# RS1xxxx register map
Vendor: Silicon Lab Inc.; Series: ARMCM4; File version: 1.2
CPU: CM4 r1p0, little endian, MPU, FPU, 6 interrupt priority bits
Registers are 32-bit, read-write, reset 0x0 unless marked. A register's access mark holds for its fields unless they carry their own. Offsets are from the block's base; [hi:lo] are bit positions; lines under a group give offsets from that group; {n}, {i} and the like mark numbered series; 'fields as' and 'values as' point back to an identical list.

## QSPI — The queued serial peripheral interface module provides a serial peripheral interface with queued transfer capability
Base 0x12000000
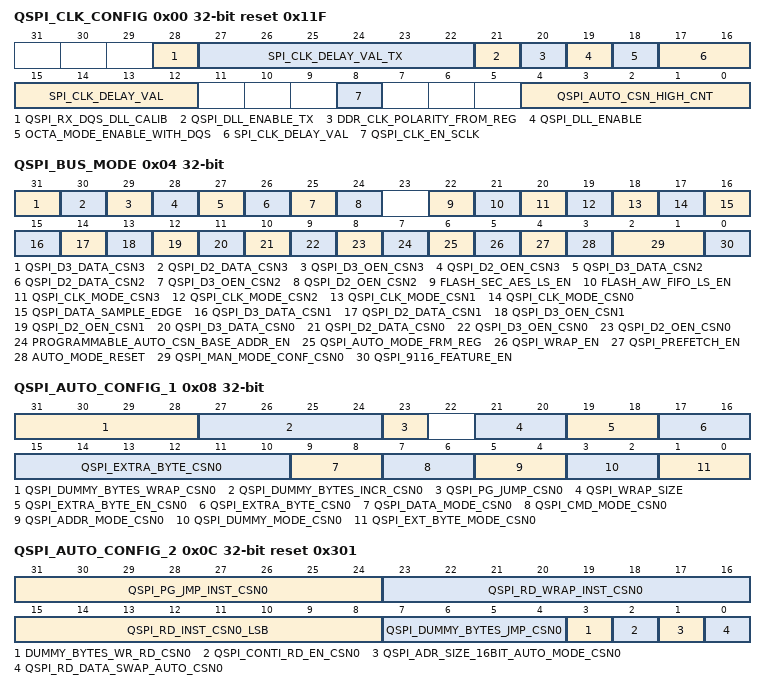
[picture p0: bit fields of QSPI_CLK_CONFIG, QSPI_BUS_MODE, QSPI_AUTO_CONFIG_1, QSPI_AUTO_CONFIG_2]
0x00 QSPI_CLK_CONFIG reset 0x11F (reset mask 0xFFF) — QSPI Clock Configuration Register
  [28] QSPI_RX_DQS_DLL_CALIB — Delay value programmed to TX QSPI DLL in write path. This delay is used to delay the qspi clock output according to the requirement
  [27:22] SPI_CLK_DELAY_VAL_TX — Delay value programmed to TX QSPI DLL in write path. This delay is used to delay the qspi clock output according to the requirement
  [21] QSPI_DLL_ENABLE_TX — Enable for TX QSPI DLL in write path. This is used in M4SS QSPI DDR pads to delay the qspi clock output. 0–DLL is disabled bypassed 1–DLL is enabled
    0=Disabled (DLL is disabled/bypassed.); 1=Enabled (DLL is enabled)
  [20] DDR_CLK_POLARITY_FROM_REG — Used this bit to sample the data at posedge negedge after interface FFs with internal qspi clock 0-Sample at negedge 1-Sample at posedge
    0=Negative_Edge (Sample at Negative edge); 1=Positive_Edge (Sample at positive edge)
  [19] QSPI_DLL_ENABLE — Enable for RX QSPI DLL in read mode.This is used in M4SS QSPI DDR pads to delay the pad clock DQS input
    values as QSPI_DLL_ENABLE_TX
  [18] OCTA_MODE_ENABLE_WITH_DQS — Enables SPI octa mode along with DQS in DDR mode
  [17:12] SPI_CLK_DELAY_VAL — Delay value programmed to RX QSPI DLL on read side. This delay is used to delay the pad clock/DQS according to the requirement
  [8] QSPI_CLK_EN_SCLK — QSPI clock enable
    0=Dynamic_Clock_Gating_Enabled (Dynamic clock gating is enabled in side QSPI controller); 1=Full_Time_Clock_Enabled (Full time clock is enabled for QSPI controller.)
  [4:0] QSPI_AUTO_CSN_HIGH_CNT — Minimum SOC clock cycles, during which QSPI auto csn should be high between consecutive CSN assertions
0x04 QSPI_BUS_MODE
  [31] QSPI_D3_DATA_CSN3 — Value of SPI_IO3 in case of dual/single mode for chip select3 csn3
  [30] QSPI_D2_DATA_CSN3 — Value of SPI_IO2 in case of dual/single mode for chip select3 csn3
  [29] QSPI_D3_OEN_CSN3 — Direction Control for SPI_IO3 in case of dual/single mode for chip select3 csn3
  [28] QSPI_D2_OEN_CSN3 — Direction Control for SPI_IO2 in case of dual/single mode for chip select3 csn3
  [27] QSPI_D3_DATA_CSN2 — Value of SPI_IO3 in case of dual/single mode for chip select2 csn2
  [26] QSPI_D2_DATA_CSN2 — Value of SPI_IO2 in case of dual/single mode for chip select2 csn2
  [25] QSPI_D3_OEN_CSN2 — Direction Control for SPI_IO3 in case of dual/single mode for chip select2 csn2
  [24] QSPI_D2_OEN_CSN2 — Direction Control for SPI_IO2 in case of dual/single mode for chip select2 csn2
  [22] FLASH_SEC_AES_LS_EN — Qspi flash auto write fifo light sleep enable
  [21] FLASH_AW_FIFO_LS_EN — Qspi flash auto write fifo light sleep enable
  [20] QSPI_CLK_MODE_CSN3 — QSPI Clock Mode
    0=Mode 0, QSPI_CLK is low when QSPI_CS is high for chip select3 csn3; 1=Mode 3, QSPI_CLK is high when QSPI_CS is high for chip select3 csn3
  [19] QSPI_CLK_MODE_CSN2 — QSPI Clock Mode
    0=Mode 0 QSPI_CLK is low when QSPI_CS is high for chip select2 csn2; 1=Mode 3 QSPI_CLK is high when QSPI_CS is high for chip select2 csn2
  [18] QSPI_CLK_MODE_CSN1 — QSPI Clock Mode
    0=Mode 0, QSPI_CLK is low when QSPI_CS is high for chip select1 csn1; 1=Mode 3, QSPI_CLK is high when QSPI_CS is high for chip select1 csn1
  [17] QSPI_CLK_MODE_CSN0 — QSPI Clock Mode
    0=Mode 0, QSPI_CLK is low when QSPI_CS is high for chip select0 csn0; 1=Mode 3, QSPI_CLK is high when QSPI_CS is high for chip select0 csn0
  [16] QSPI_DATA_SAMPLE_EDGE — Samples MISO data on clock edges
    0=Disable (Pos edge of loop back spi_pad_clk); 1=Enable (Neg edge of loop back spi_pad_clk)
  [15] QSPI_D3_DATA_CSN1 — Value of SPI_IO3 in case of dual/single mode for chip select1 csn1
  [14] QSPI_D2_DATA_CSN1 — Direction Control for SPI_IO3 in case of dual/single mode for chip select1 csn1
  [13] QSPI_D3_OEN_CSN1 — Direction Control for SPI_IO3 in case of dual/single mode for chip select1 csn1
  [12] QSPI_D2_OEN_CSN1 — Direction Control for SPI_IO2 in case of dual/single mode for chip select1 csn1
  [11] QSPI_D3_DATA_CSN0 — Value of SPI_IO3 in case of dual/single mode for chip select0 csn0. It is used both in Auto and Manual Mode
  [10] QSPI_D2_DATA_CSN0 — Value of SPI_IO2 in case of dual/single mode for chip select0 csn0. It is used both in Auto and Manual Mode.
  [9] QSPI_D3_OEN_CSN0 — Direction Control for SPI_IO3 in case of dual/single mode for chip select0 csn0. It is used both in Auto and Manual Mode.
  [8] QSPI_D2_OEN_CSN0 — Direction Control for SPI_IO2 in case of dual/single mode for chip select0 csn0. It is used both in Auto and Manual Mode
  [7] PROGRAMMABLE_AUTO_CSN_BASE_ADDR_EN — Programmable auto csn mode enable
  [6] QSPI_AUTO_MODE_FRM_REG — QSPI Mode of Operation
    0=Disable (Manual Mode is selected); 1=Enable (Auto Mode is selected.)
  [5] QSPI_WRAP_EN — Model wrap is considered with this bit and uses wrap instruction to read from FLASH
    0=Disable (Wrap mode is disabled (AHB WRAP can be used).); 1=Enable (Wrap mode is enabled)
  [4] QSPI_PREFETCH_EN — Pre-fetch of data from the model which is connected to QSPI, automatically with out reading on AHB and is supplied to AHB, when address is matched with AHB read transaction address
    0=Disable (Pre-fetch mode is disabled.); 1=Enable (Pre-fetch mode is enabled)
  [3] AUTO_MODE_RESET — QSPI Auto controller reset. This is not a Self clearing bit
    0=Disable (Auto mode is active); 1=Enable (Auto mode is inactive)
  [2:1] QSPI_MAN_MODE_CONF_CSN0 — Configures the QSPI flash for Single/Dual/Quad mode operation in manual mode
    0=Single Mode; 1=Dual Mode; 2=Quad Mode; 3=none
  [0] QSPI_9116_FEATURE_EN — 9115 specific features are enabled with this enable
0x08 QSPI_AUTO_CONFIG_1 (reset mask 0xFF8FFFFF) — QSPI Auto Controller Configuration 1 Register
  [31:28] QSPI_DUMMY_BYTES_WRAP_CSN0 — Specifies the number of dummy bytes 0 to 7 for the selected SPI mode in case of wrap instruction
  [27:24] QSPI_DUMMY_BYTES_INCR_CSN0 — Specifies the number of dummy bytes 0 to 7 for the selected SPI mode
  [23] QSPI_PG_JUMP_CSN0
  [21:20] QSPI_WRAP_SIZE — Qspi auto wrap size
  [19:18] QSPI_EXTRA_BYTE_EN_CSN0 — Value of the extra byte to be transmitted, if the extra byte mode is enabled
    0=Do not transmit extra byte; 1=Transmit Extra byte after address phase; 2=Transmit only first nibble of the byte and maintain Hi-Z on the IO bus for next nibble; 3=none
  [17:10] QSPI_EXTRA_BYTE_CSN0 — Value of the extra byte to be transmitted, if the extra byte mode is enabled
  [9:8] QSPI_DATA_MODE_CSN0 — Mode of operation of QSPI in DATA phase
    0=SPI; 1=Dual SPI; 2=Quad SPI; 3=none
  [7:6] QSPI_CMD_MODE_CSN0 — Mode of operation of QSPI in instruction phase
    0=SPI; 1=Dual SPI; 2=Quad SPI; 3=none
  [5:4] QSPI_ADDR_MODE_CSN0 — Mode of operation of QSPI in instruction phase
    0=SPI; 1=Dual SPI; 2=Quad SPI; 3=none
  [3:2] QSPI_DUMMY_MODE_CSN0 — Mode of operation of QSPI in instruction phase
    0=SPI; 1=Dual SPI; 2=Quad SPI; 3=none
  [1:0] QSPI_EXT_BYTE_MODE_CSN0 — Mode of operation of QSPI in the extra byte phase
    0=SPI; 1=Dual SPI; 2=Quad SPI; 3=none
0x0C QSPI_AUTO_CONFIG_2 reset 0x301 — QSPI Auto Controller Configuration 2 Register
  [31:24] QSPI_PG_JMP_INST_CSN0 — Read instruction to be used, when Page jump is to be used
  [23:16] QSPI_RD_WRAP_INST_CSN0 — Read instruction to be used, when wrap mode is supported by QSPI flash
  [15:8] QSPI_RD_INST_CSN0_LSB — Read instruction LS Byte to be used for the selected SPI modes and when wrap is not supported
  [7:4] QSPI_DUMMY_BYTES_JMP_CSN0 — Dummy cycles to be selected in case of JUMP
  [3] DUMMY_BYTES_WR_RD_CSN0 — Dummy bytes to the model to be read or to be write
    0=Disable (Dummy bytes will be read); 1=Enable (Dummy bytes to be write.)
  [2] QSPI_CONTI_RD_EN_CSN0
    0=Disabled (Continuous read disabled.); 1=Enabled (Continuous read enabled.)
  [1] QSPI_ADR_SIZE_16BIT_AUTO_MODE_CSN0
    0=Disable (24 bit address is sent to model); 1=Enable (16 Bit address is sent to model)
  [0] QSPI_RD_DATA_SWAP_AUTO_CSN0
    0=Disable (Do not swap the read data in auto mode); 1=Enable (Swap the auto read data in auto mode)
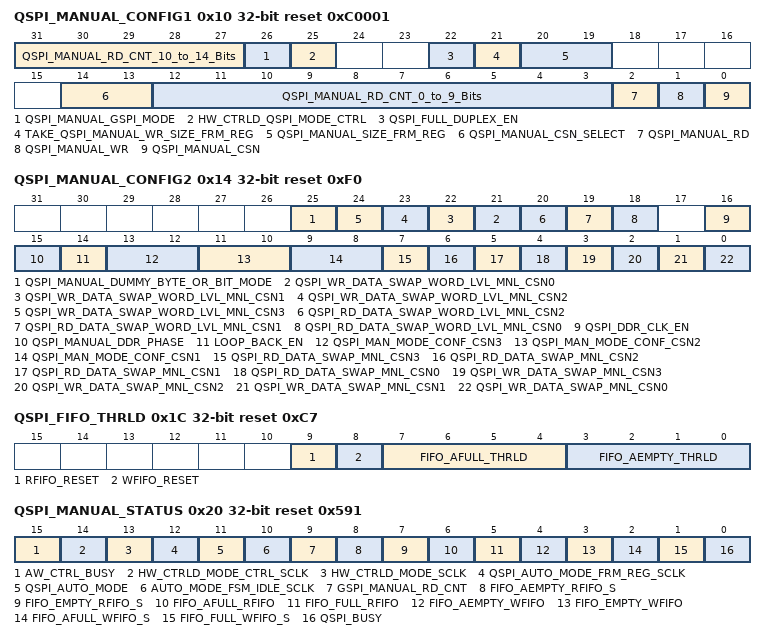
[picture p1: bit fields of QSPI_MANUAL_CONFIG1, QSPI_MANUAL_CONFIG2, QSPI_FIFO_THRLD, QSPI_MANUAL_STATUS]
0x10 QSPI_MANUAL_CONFIG1 reset 0xC0001 — QSPI Manual Configuration 1 Register
  [31:27] QSPI_MANUAL_RD_CNT_10_to_14_Bits — Indicates total number of bytes or bits
  [26] QSPI_MANUAL_GSPI_MODE — Internally the priority is given to manual mode
    0=SPI_Mode; 1=Host_SPI_Mode
  [25] HW_CTRLD_QSPI_MODE_CTRL — Hardware controlled qspi mode in between AUTO and manual
    0=Disabled (Hardware control is disabled); 1=Enabled (Hardware control is enabled.)
  [22] QSPI_FULL_DUPLEX_EN — Full duplex mode enable.
    0=Disable (Full duplex mode disabled.); 1=Enable (Full duplex mode enabled)
  [21] TAKE_QSPI_MANUAL_WR_SIZE_FRM_REG
    0=Disable (No action. Takes write size from fifo); 1=Enable (Take write size from Manual config register1)
  [20:19] QSPI_MANUAL_SIZE_FRM_REG — Manual reads and manual writes follow this size
  [14:13] QSPI_MANUAL_CSN_SELECT — Indicates which CSn is valid
  [12:3] QSPI_MANUAL_RD_CNT_0_to_9_Bits — Indicates total number of bytes to be read along with [31:27] bits of this register. Maximum length supported is 32k bytes
  [2] QSPI_MANUAL_RD — Read enable for manual mode when CS is low
  [1] QSPI_MANUAL_WR — Write enable for manual mode when CS is low
  [0] QSPI_MANUAL_CSN — SPI CS in manual mode
0x14 QSPI_MANUAL_CONFIG2 reset 0xF0 (reset mask 0xFFF) — QSPI Manual Configuration 2 Register
  [25] QSPI_MANUAL_DUMMY_BYTE_OR_BIT_MODE — Indicates qspi_manual_rd_cnt values are dummy bytes or bits in manual mode.
  [n+21] QSPI_WR_DATA_SWAP_WORD_LVL_MNL_CSN{n} (n=0..3) — Set this bit for write data byte swapping within the word. It is valid only for octa ddr mode. It is valid for csn{n}.
  [20] QSPI_RD_DATA_SWAP_WORD_LVL_MNL_CSN2 — Set this bit for read data byte swapping within the word. It is valid only for octa ddr mode. It is valid for csn2.
  [19] QSPI_RD_DATA_SWAP_WORD_LVL_MNL_CSN1 — Set this bit for read data byte swapping within the word. It is valid only for octa ddr mode. It is valid for csn1.
  [18] QSPI_RD_DATA_SWAP_WORD_LVL_MNL_CSN0 — Set this bit for read data byte swapping within the word. It is valid only for octa ddr mode. It is valid for csn0.
  [16] QSPI_DDR_CLK_EN — DDR operations can be performed even in manual mode
    0=Disable (Use SDR mode clk); 1=Enable (Use DDR mode clk)
  [15] QSPI_MANUAL_DDR_PHASE — DDR operations can be performed even in manual mode
  [14] LOOP_BACK_EN — Internal loop back test mode.
  [13:12] QSPI_MAN_MODE_CONF_CSN3 — Configures the QSPI flash for Single or Dual or Quad mode operation in manual mode for chip select3 csn3
    0=Single; 1=Dual; 2=Quad; 3=none
  [11:10] QSPI_MAN_MODE_CONF_CSN2 — Configures the QSPI flash for Single or Dual or Quad mode operation in manual mode for chip select2 csn2
    0=Single; 1=Dual; 2=Quad; 3=none
  [9:8] QSPI_MAN_MODE_CONF_CSN1 — Configures the QSPI flash for Single/Dual/Quad mode operation in manual mode for chip select1 csn1
    0=Single; 1=Dual; 2=Quad; 3=none
  [7] QSPI_RD_DATA_SWAP_MNL_CSN3 — Swap the read data inside the QSPIcontroller itself
    0=Disable (Manual read data swap is disabled for csn3); 1=Enable (Manual read data swap is enabled for csn3)
  [6] QSPI_RD_DATA_SWAP_MNL_CSN2 — Swap the read data inside the QSPIcontroller it-self
    0=Disable (Manual read data swap is disabled for csn2); 1=Enable (Manual read data swap is enabled for csn2)
  [5] QSPI_RD_DATA_SWAP_MNL_CSN1 — Swap the read data inside the QSPIcontroller itself.
    0=Disable (Manual read data swap is disabled for csn1); 1=Enable (Manual read data swap is enabled for csn1)
  [4] QSPI_RD_DATA_SWAP_MNL_CSN0 — Swap the read data inside the QSPIcontroller it self.
    0=Disable (Manual read data swap is disabled for csn0.); 1=Enable (Manual read data swap is enabled for csn0.)
  [3] QSPI_WR_DATA_SWAP_MNL_CSN3 — Swap the write data inside the QSPI controller itself.
    0=Disable (Manual write data swap is disabled for csn3.); 1=Enable (Manual write data swap is enabled for csn3.)
  [2] QSPI_WR_DATA_SWAP_MNL_CSN2 — Swap the write data inside the QSPI controller itself.
    0=Disable (Manual write data swap is disabled for csn2.); 1=Enable (Manual write data swap is enabled for csn2.)
  [1] QSPI_WR_DATA_SWAP_MNL_CSN1 — Swap the write data inside the QSPI controller it-self.
    0=Disable (Manual write data swap is disabled for csn1.); 1=Enable (Manual write data swap is enabled for csn1.)
  [0] QSPI_WR_DATA_SWAP_MNL_CSN0 — Swap the write data inside the QSPI controller it-self
    0=Disable (Manual write data swap is disabled for csn0.); 1=Enable (Manual write data swap is enabled for csn0.)
0x1C QSPI_FIFO_THRLD reset 0xC7 (reset mask 0x1FF) — QSPI FIFO Threshold Register
  [9] RFIFO_RESET — Read fifo reset
  [8] WFIFO_RESET — Write fifo reset
  [7:4] FIFO_AFULL_THRLD — FIFO almost full threshold
  [3:0] FIFO_AEMPTY_THRLD — FIFO almost empty threshold
0x20 QSPI_MANUAL_STATUS ro reset 0x591 (reset mask 0x7FFF)
  [15] AW_CTRL_BUSY — Auto write busy indication.
  [14] HW_CTRLD_MODE_CTRL_SCLK — HW_CTRLD_MODE status
    0=Disable (HW_CTRL_MODE is disabled.); 1=Enable (HW_CTRL_MODE is enabled)
  [13] HW_CTRLD_MODE_SCLK — QSPI mode status in HW_CTRLD_MODE
    0=Disable (QSPI controller is in MANUAL mode.); 1=Enable (QSPI controller is working in AUTO MODE.)
  [12] QSPI_AUTO_MODE_FRM_REG_SCLK — QSPI auto mode status. Valid only when HW_CTRLD_QSPI_MODE_CTRL is zero.
    0=Disable (QSPI controller is hot coded to manual mode operations.); 1=Enable (QSPI controller is hot coded to AUTO mode operations)
  [11] QSPI_AUTO_MODE — QSPI controller status.
    0=Disable (QSPI controller is in manual mode.); 1=Enable (QSPI controller is in auto mode.)
  [10] AUTO_MODE_FSM_IDLE_SCLK — Auto mode idle signal to track auto controller is busy or idle.
    0=Disable (Auto mode is busy); 1=Enable (Auto mode is idle)
  [9] GSPI_MANUAL_RD_CNT — This is a result of 10 bits ORing counter
    0=Disable (No read transactions are in pending); 1=Enable (Read transactions are in pending ( to be done))
  [8] FIFO_AEMPTY_RFIFO_S — Status indication for Rfifo in manual mode
  [7] FIFO_EMPTY_RFIFO_S — Status indication for Rfifo in manual mode
  [6] FIFO_AFULL_RFIFO — Status indication for Rfifo in manual mode
  [5] FIFO_FULL_RFIFO — Status indication for Rfifo in manual mode
  [4] FIFO_AEMPTY_WFIFO — Status indication for Wfifo in manual mode
  [3] FIFO_EMPTY_WFIFO — Status indication for Wfifo in manual mode
  [2] FIFO_AFULL_WFIFO_S — Status indication for Wfifo in manual mode
  [1] FIFO_FULL_WFIFO_S — Status indication for Wfifo in manual mode
  [0] QSPI_BUSY — State of Manual mode.
    0=Disable (QSPI controller is IDLE in Manual mode.); 1=Enable (A read, write or dummy cycle operation is in process in manual mode.)
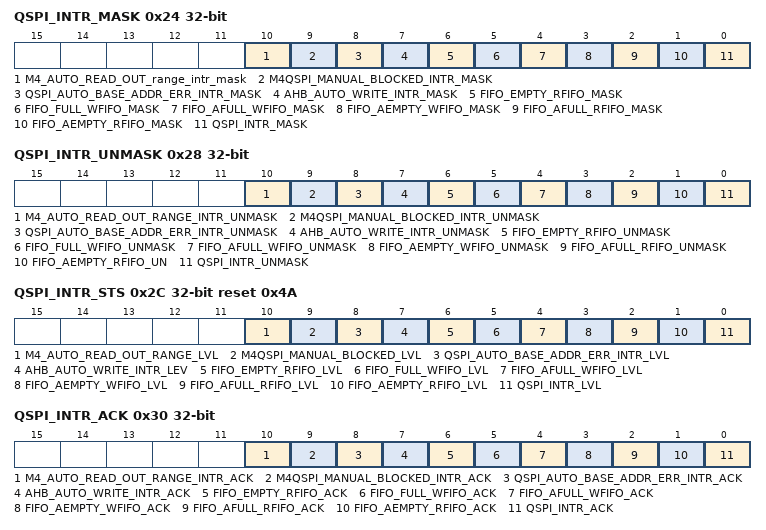
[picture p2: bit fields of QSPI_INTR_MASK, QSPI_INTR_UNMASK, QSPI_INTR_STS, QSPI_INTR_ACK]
0x24 QSPI_INTR_MASK (reset mask 0x6F) — QSPI Interrupt Mask Register
  [10] M4_AUTO_READ_OUT_range_intr_mask — Rising interrupt when M4 QSPI tries to read TA locations in Common flash mode (3). This bit is a mask for this interrupt.
  [9] M4QSPI_MANUAL_BLOCKED_INTR_MASK — Rising interrupt when M4 QSPI tries to do manual mode transactions in Common flash mode (3). This bit is a mask for this interrupt.
  [8] QSPI_AUTO_BASE_ADDR_ERR_INTR_MASK — Rising interrupt when no csn is selected using programmable auto base address. This bit is a mask for this interrupt.
  [7] AHB_AUTO_WRITE_INTR_MASK — Rising interrupt for any auto write operation on AHB bus. This bit is a mask for this interrupt
  [6] FIFO_EMPTY_RFIFO_MASK
    0=Disable (Do not touch); 1=Enable (Read fifo is empty intr mask)
  [5] FIFO_FULL_WFIFO_MASK
    0=Disable (Do not touch); 1=Enable (write fifo full intr mask)
  [4] FIFO_AFULL_WFIFO_MASK
    0=Disable (Do not touch); 1=Enable (Write fifo almost full intr mask)
  [3] FIFO_AEMPTY_WFIFO_MASK
    0=Disable (Do not touch); 1=Enable (write fifo almost empty intr mask.)
  [2] FIFO_AFULL_RFIFO_MASK
    0=Disable (Do not touch); 1=Enable (read fifo almost full intr mask)
  [1] FIFO_AEMPTY_RFIFO_MASK
    0=Disable (Do not touch); 1=Enable (Read fifo almost empty intr mask.)
  [0] QSPI_INTR_MASK — Interrupt Status bit
    0=Disable (Do not touch); 1=Enable (mask the qspi intr)
0x28 QSPI_INTR_UNMASK (reset mask 0x7F) — QSPI Interrupt Unmask Register
  [10] M4_AUTO_READ_OUT_RANGE_INTR_UNMASK — Rising interrupt when M4 QSPI tries to read TA locations in Common flash mode (3). This bit is a unmask for this interrupt.
  [9] M4QSPI_MANUAL_BLOCKED_INTR_UNMASK — Rising interrupt when M4 QSPI tries to do manual mode transactions in Common flash mode (3). This bit is a unmask for this interrupt.
  [8] QSPI_AUTO_BASE_ADDR_ERR_INTR_UNMASK — Rising interrupt when M4 QSPI tries to do manual mode transactions in Common flash mode (3). This bit is a unmask for this interrupt.
  [7] AHB_AUTO_WRITE_INTR_UNMASK — Rising interrupt for any auto write operation on AHB bus. This bit is a unmask for this interrupt.
  [6] FIFO_EMPTY_RFIFO_UNMASK
    0=Disable (Do not touch); 1=Enable (Read fifo is empty intr unmask)
  [5] FIFO_FULL_WFIFO_UNMASK
    0=Disable (Do not touch); 1=Enable (write fifo full intr unmask)
  [4] FIFO_AFULL_WFIFO_UNMASK
    0=Disable (Do not touch); 1=Enable (Write fifo almost full intr unmask.)
  [3] FIFO_AEMPTY_WFIFO_UNMASK
    0=Disable (Do not touch); 1=Enable (write fifo almost empty intr unmask)
  [2] FIFO_AFULL_RFIFO_UNMASK
    0=Disable (Do not touch); 1=Enable (read fifo almost full intr unmask.)
  [1] FIFO_AEMPTY_RFIFO_UN
    0=Disable (Do not touch); 1=Enable (Read fifo almost empty intr unmask)
  [0] QSPI_INTR_UNMASK — Interrupt Status bit
    0=Disable (Do not touch); 1=Enable (unmask the qspi intr)
0x2C QSPI_INTR_STS ro reset 0x4A (reset mask 0x7F) — QSPI Interrupt Status Register
  [10] M4_AUTO_READ_OUT_RANGE_LVL — Rising interrupt when M4 QSPI tries to read TA locations in Common flash mode (3).
  [9] M4QSPI_MANUAL_BLOCKED_LVL — Rising interrupt when M4 QSPI tries to do manual mode transactions in Common flash mode (3).
  [8] QSPI_AUTO_BASE_ADDR_ERR_INTR_LVL — Rising interrupt when no csn is selected using programmable auto base address.
  [7] AHB_AUTO_WRITE_INTR_LEV — rising interrupt for any auto write operation on AHB bus.
  [6] FIFO_EMPTY_RFIFO_LVL
    0=Disable (Read FIFO is not empty); 1=Enable (Read FIFO is empty)
  [5] FIFO_FULL_WFIFO_LVL
    0=Disable (Write fifo not got full); 1=Enable (write fifo got full.)
  [4] FIFO_AFULL_WFIFO_LVL
    0=Disable (write FIFO not reached almost full threshold); 1=Enable (Write FIFO reached almost full threshold)
  [3] FIFO_AEMPTY_WFIFO_LVL
    0=Disable (write FIFO not reached almost full threshold.); 1=Enable (write FIFO reached almost empty threshold.)
  [2] FIFO_AFULL_RFIFO_LVL
    0=Disable (read FIFO do not reached almost full threshold); 1=Enable (read FIFO reached almost full threshold)
  [1] FIFO_AEMPTY_RFIFO_LVL
    0=Disable (Read fifo does not reached almost empty threshold); 1=Enable (Read fifo reached almost empty threshold)
  [0] QSPI_INTR_LVL — Interrupt Status bit
    0=Disable (no interrupt); 1=Enable (qspi raised a interrupt)
0x30 QSPI_INTR_ACK (reset mask 0x7F) — QSPI Interrupt Acknowledge Register
  [10] M4_AUTO_READ_OUT_RANGE_INTR_ACK — Rising interrupt when M4 QSPI tries to read TA locations in Common flash mode (3). This bit is an ack for this interrupt.
  [9] M4QSPI_MANUAL_BLOCKED_INTR_ACK — Rising interrupt when M4 QSPI tries to do manual mode transactions in Common flash mode (3). This bit is an ack for this interrupt.
  [8] QSPI_AUTO_BASE_ADDR_ERR_INTR_ACK wo — Rising interrupt when no csn is selected using programmable auto base address. This bit is an ack for this interrupt.
  [7] AHB_AUTO_WRITE_INTR_ACK wo — Rising interrupt for any auto write operation on AHB bus. This bit is an ack for this interrupt.
  [6] FIFO_EMPTY_RFIFO_ACK wo
    values as QSPI_INTR_UNMASK.FIFO_EMPTY_RFIFO_UNMASK
  [5] FIFO_FULL_WFIFO_ACK wo
    values as QSPI_INTR_UNMASK.FIFO_FULL_WFIFO_UNMASK
  [4] FIFO_AFULL_WFIFO_ACK wo
    values as QSPI_INTR_UNMASK.FIFO_AFULL_WFIFO_UNMASK
  [3] FIFO_AEMPTY_WFIFO_ACK wo
    0=Disable (Do not touch); 1=Enable (write fifo almost empty intr unmask.)
  [2] FIFO_AFULL_RFIFO_ACK wo
    values as QSPI_INTR_UNMASK.FIFO_AFULL_RFIFO_UNMASK
  [1] FIFO_AEMPTY_RFIFO_ACK wo
    values as QSPI_INTR_UNMASK.FIFO_AEMPTY_RFIFO_UN
  [0] QSPI_INTR_ACK wo — Interrupt Status bit
    0=Disable (Do not touch); 1=Enable (unmask the qspi intr.)
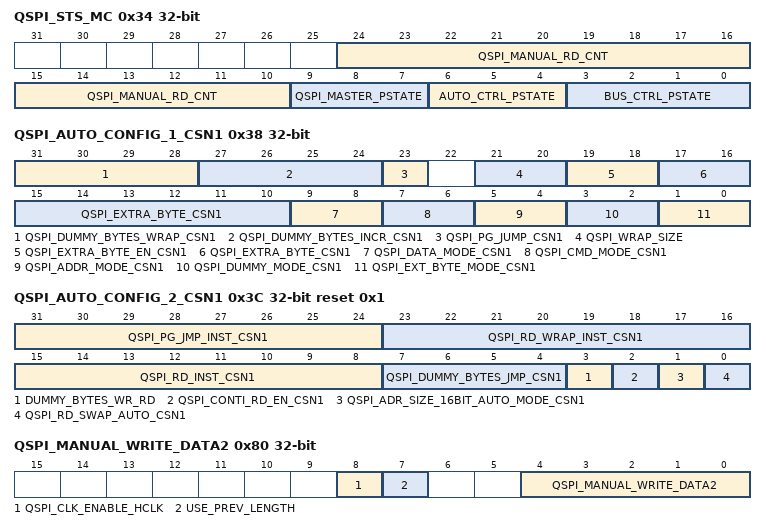
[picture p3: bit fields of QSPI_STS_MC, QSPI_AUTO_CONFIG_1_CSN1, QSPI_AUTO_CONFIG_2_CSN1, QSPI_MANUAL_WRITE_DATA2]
0x34 QSPI_STS_MC ro (reset mask 0x6FF) — QSPI State Machine Monitor Register
  [24:10] QSPI_MANUAL_RD_CNT — Qspi manual read counter value
  [9:7] QSPI_MASTER_PSTATE — Qspi master present state
  [6:4] AUTO_CTRL_PSTATE — Auto controller present state
  [3:0] BUS_CTRL_PSTATE — Bus controller present state
0x38 QSPI_AUTO_CONFIG_1_CSN1 (reset mask 0x87FFFF) — QSPI Auto Controller Configuration 1 CSN1 Register
  [31:28] QSPI_DUMMY_BYTES_WRAP_CSN1 ro — Specifies the number of dummy bytes 0 to 7 for the selected SPI mode in case of wrap instruction.
  [27:24] QSPI_DUMMY_BYTES_INCR_CSN1 ro — Specifies the number of dummy bytes 0 to 7 for the selected SPI mode.
  [23] QSPI_PG_JUMP_CSN1 wo
    0=Disable (Do not use Index jump instruction.); 1=Enable (Use Index jump instruction specified by QSPI_PG_JUMP_INST)
  [21:20] QSPI_WRAP_SIZE — Qspi auto wrap size
  [19:18] QSPI_EXTRA_BYTE_EN_CSN1 — Mode of operation of QSPI in DATA phase.
    values as QSPI_AUTO_CONFIG_1.QSPI_EXTRA_BYTE_EN_CSN0
  [17:10] QSPI_EXTRA_BYTE_CSN1 ro — Value of the extra byte to be transmitted, if the extra byte mode is enabled.
  [9:8] QSPI_DATA_MODE_CSN1 — Mode of operation of QSPI in DATA phase.
    0=SPI; 1=Dual SPI; 2=Quad SPI; 3=none
  [7:6] QSPI_CMD_MODE_CSN1 — Mode of operation of QSPI in instruction phase.
    0=SPI; 1=Dual SPI; 2=Quad SPI; 3=none
  [5:4] QSPI_ADDR_MODE_CSN1 — Mode of operation of QSPI in instruction phase.
    0=SPI; 1=Dual SPI; 2=Quad SPI; 3=none
  [3:2] QSPI_DUMMY_MODE_CSN1 — Mode of operation of QSPI in instruction phase
    0=SPI; 1=Dual SPI; 2=Quad SPI; 3=none
  [1:0] QSPI_EXT_BYTE_MODE_CSN1 — Mode of operation of QSPI in instruction phase.
    0=SPI; 1=Dual SPI; 2=Quad SPI; 3=none
0x3C QSPI_AUTO_CONFIG_2_CSN1 reset 0x1 — QSPI Auto Controller Configuration 2 CSN1 Register
  [31:24] QSPI_PG_JMP_INST_CSN1 — Read instruction to be used, when Page jump is to be used.
  [23:16] QSPI_RD_WRAP_INST_CSN1 — Read instruction to be used for the selected SPI modes and when wrap is not needed or supported
  [15:8] QSPI_RD_INST_CSN1 — Read instruction to be used for the selected SPI modes and when wrap is not needed or supported
  [7:4] QSPI_DUMMY_BYTES_JMP_CSN1 — Dummy cycles to be selected in case of JUMP
  [3] DUMMY_BYTES_WR_RD — Dummy bytes to the model to be read or to be write.
  [2] QSPI_CONTI_RD_EN_CSN1 — Continuous read enable bit.
  [1] QSPI_ADR_SIZE_16BIT_AUTO_MODE_CSN1
  [0] QSPI_RD_SWAP_AUTO_CSN1 — Swap the read data from the flash in byte order for chip select1 csn1 in auto mode.
    0=Swap_Disable (Swap is disabled.); 1=Swap_Enable (Swap is enabled)
0x80 QSPI_MANUAL_WRITE_DATA2 (reset mask 0xFF)
  [8] QSPI_CLK_ENABLE_HCLK — reserved2
  [7] USE_PREV_LENGTH — Use previous length.
    0=Disable (No action); 1=Enable (Uses previously programmed length in [4:0] of this register for next writes)
  [4:0] QSPI_MANUAL_WRITE_DATA2 — Number of bits to be written in write mode
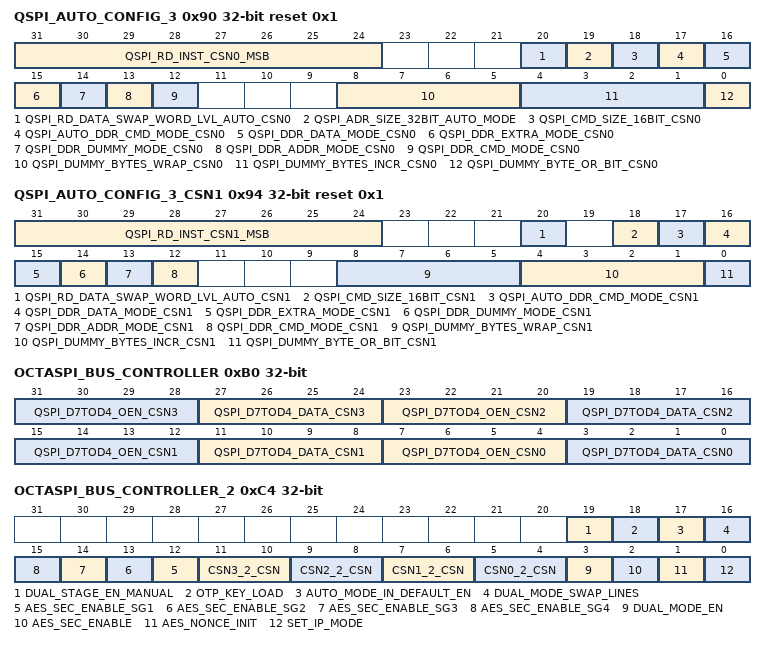
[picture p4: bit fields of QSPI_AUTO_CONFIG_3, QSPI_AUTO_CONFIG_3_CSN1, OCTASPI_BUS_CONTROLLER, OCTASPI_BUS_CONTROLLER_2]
0x90 QSPI_AUTO_CONFIG_3 reset 0x1 — QSPI Auto Controller Configuration 3 CSN0 Register
  [31:24] QSPI_RD_INST_CSN0_MSB — Read instruction MS byte to be used the selected SPI modes and when wrap is not needed or supported.
  [20] QSPI_RD_DATA_SWAP_WORD_LVL_AUTO_CSN0 — Rd data swap at word level in auto mode for csn0. It is valid for octa mode.
  [19] QSPI_ADR_SIZE_32BIT_AUTO_MODE — 32 bit addressing support enable.
  [18] QSPI_CMD_SIZE_16BIT_CSN0 — Enable for 16 read cmd size for csn0.
  [17] QSPI_AUTO_DDR_CMD_MODE_CSN0 — DDR data mode.
  [16] QSPI_DDR_DATA_MODE_CSN0 — DDR Address mode
    0=Disable (Data are sampled in SDR fashion); 1=Enable (Data are sampled in DDR fashion)
  [15] QSPI_DDR_EXTRA_MODE_CSN0 — DDR Address mode
    0=Disable (Extra byte is driven in SDR fashion); 1=Enable (Extra byte is driven in DDR fashion)
  [14] QSPI_DDR_DUMMY_MODE_CSN0 — DDR Address mode
    0=Disable (Dummy bytes are driven in SDR fashion); 1=Enable (Dummy bytes are driven in DDR fashion.)
  [13] QSPI_DDR_ADDR_MODE_CSN0 — DDR Address mode
    0=Disable (Address bytes are driven in SDR fashion); 1=Enable (Address bytes are driven in DDR fashion)
  [12] QSPI_DDR_CMD_MODE_CSN0 — DDR Command mode
    0=Disable (Command byte is driven in SDR fashion); 1=Enable (Command byte is driven in DDR fashion.)
  [8:5] QSPI_DUMMY_BYTES_WRAP_CSN0 — Specifies the number of dummy bytes for the selected SPI mode in case of wrap instruction. It contains MS nibble for byte.
  [4:1] QSPI_DUMMY_BYTES_INCR_CSN0 — Specifies the number of dummy bytes for the selected SPI mode. It contains MS nibble for byte.
  [0] QSPI_DUMMY_BYTE_OR_BIT_CSN0 — Indicates all above mention values are dummy bytes or bits in auto mode.
0x94 QSPI_AUTO_CONFIG_3_CSN1 reset 0x1 — QSPI Auto Controller Configuration 3 CSN1 Register
  [31:24] QSPI_RD_INST_CSN1_MSB — Read instruction MS byte to be used the selected SPI modes and when wrap is not needed or supported.
  [20] QSPI_RD_DATA_SWAP_WORD_LVL_AUTO_CSN1 — Rd data swap at word level in auto mode for csn1. It is valid for octa mode.
  [18] QSPI_CMD_SIZE_16BIT_CSN1 — Enable for 16 read cmd size for csn1.
  [17] QSPI_AUTO_DDR_CMD_MODE_CSN1 — DDR data mode.
  [16] QSPI_DDR_DATA_MODE_CSN1 — DDR Address mode
    0=Data are sampled in SDR fashion; 1=Data are sampled in DDR fashion
  [15] QSPI_DDR_EXTRA_MODE_CSN1 — DDR Address mode
    0=Extra byte is driven in SDR fashion; 1=Extra byte is driven in DDR fashion
  [14] QSPI_DDR_DUMMY_MODE_CSN1 — DDR Address mode
    0=Dummy bytes are driven in SDR fashion; 1=Dummy bytes are driven in DDR fashion
  [13] QSPI_DDR_ADDR_MODE_CSN1 — DDR Address mode
    0=Address bytes are driven in SDR fashion; 1=Address bytes are driven in DDR fashion
  [12] QSPI_DDR_CMD_MODE_CSN1 — DDR Command mode
    0=Command byte is driven in SDR fashion; 1=Command byte is driven in DDR fashion
  [8:5] QSPI_DUMMY_BYTES_WRAP_CSN1 — Specifies the number of dummy bytes for the selected SPI mode in case of wrap instruction. It contains MS nibble for byte.
  [4:1] QSPI_DUMMY_BYTES_INCR_CSN1 — Specifies the number of dummy bytes for the selected SPI mode. It contains MS nibble for byte.
  [0] QSPI_DUMMY_BYTE_OR_BIT_CSN1 — Indicates all above mention values are dummy bytes or bits in auto mode.
0xA0 QSPI_AUTO_BASE_ADDR_CSN0
  [31:0] QSPI_AUTO_BASE_ADDR_CSN0 — Holds the 32 bit base address for select chip select0 in programmable auto csn mode. It is valid only programmable auto csn mode is enabled.
0xA4 QSPI_AUTO_BASE_ADDR_CSN1
  [31:0] QSPI_AUTO_BASE_ADDR_CSN1 — Holds the 32 bit base address for select chip select1 in programmable auto csn mode. It is valid only programmable auto csn mode is enabled.
0xB0 OCTASPI_BUS_CONTROLLER
  [8n+7:8n+4] QSPI_D7TOD4_OEN_CSN{n} (n=0..3) — Direction Control for SPI_IO 7,6,5 and 4 in case of quad/dual/single mode for chip select{n} (cs_n{n}). It is used both in Auto and Manual Mode.
  [27:24] QSPI_D7TOD4_DATA_CSN3 — Value of SPI_IO7,6,5 and 4 in case of quad/dual/single mode for chip select3 (cs_n3). It is used both in Auto and Manual Mode.
  [19:16] QSPI_D7TOD4_DATA_CSN2 — Value of SPI_IO7,6,5 and 4 in case of quad/dual/single mode for chip select2 (cs_n2). It is used both in Auto and Manual Mode.
  [11:8] QSPI_D7TOD4_DATA_CSN1 — Value of SPI_IO7,6,5 and 4 in case of quad/dual/single mode for chip select1 (cs_n1). It is used both in Auto and Manual Mode.
  [3:0] QSPI_D7TOD4_DATA_CSN0 — Value of SPI_IO7,6,5 and 4 in case of quad/dual/single mode for chip select1 (cs_n0). It is used both in Auto and Manual Mode.
0xB4 QSPI_AUTO_BASE_ADDR_UNMASK_CSN0 reset 0xFFFFFFFF
  [31:0] QSPI_AUTO_BASE_ADDR_UNMASK_CSN0 — Holds the 32 bit base address unmask value for select chip select0 in programmable auto csn mode. It is valid only programmable auto csn mode is enabled.
0xB8 QSPI_AUTO_BASE_ADDR_UNMASK_CSN1 reset 0xFFFFFFFF
  [31:0] QSPI_AUTO_BASE_ADDR_UNMASK_CSN1 — Holds the 32 bit base address unmask value for select chip select1 in programmable auto csn mode. It is valid only programmable auto csn mode is enabled.
0xC4 OCTASPI_BUS_CONTROLLER_2
  [19] DUAL_STAGE_EN_MANUAL — Dual stage en for dual flash mode
  [18] OTP_KEY_LOAD — Enable to load key from OTP/KH
  [17] AUTO_MODE_IN_DEFAULT_EN — Qspi works in auto mode if set this is bit by default.
  [16] DUAL_MODE_SWAP_LINES — This bit controls the 8 lines of qspi with 4 bit swap manner
  [n+11] AES_SEC_ENABLE_SG{n} (n=1..4) — This bit enables the AES security enable or not for segment {n}
  [11:10] CSN3_2_CSN — Map csn3 to the programmed csn. It is valid for both manual and auto modes
    0=Map csn3 to csn0. Reads on csn3 will have data from csn0 also.; 1=Map csn3 to csn1. Reads on csn3 will have data from csn0 also; 2=Map csn3 to csn2. Reads on csn3 will have data from csn0 also.; 3=Not valid
  [9:8] CSN2_2_CSN — Map csn2 to the programmed csn. It is valid for both manual and auto modes
    0=Map csn2 to csn1. Reads on csn2 will have data from csn0 also; 1=Map csn2 to csn1. Reads on csn2 will have data from csn1 also; 2=Not valid; 3=Map csn2 to csn3. Reads on csn2 will have data from csn3 also.
  [7:6] CSN1_2_CSN — Map csn1 to the programmed csn. It is valid for both manual and auto modes
    0=Map csn1 to csn0. Reads on csn1 will have data from csn1 also; 1=Not valid; 2=Map csn1 to csn2. Reads on csn1 will have data from csn2 also; 3=Map csn1 to csn3. Reads on csn1 will have data from csn3 also
  [5:4] CSN0_2_CSN — Map csn0 to the programmed csn. It is valid for both manual and auto modes
    0=Not valid; 1=Map csn0 to csn1. Reads on csn0 will have data from csn1 also; 2=Map csn0 to csn2. Reads on csn0 will have data from csn2 also; 3=Map csn0 to csn3. Reads on csn0 will have data from csn3 also
  [3] DUAL_MODE_EN — Dual flash mode enable control.
  [2] AES_SEC_ENABLE — This bit enables the AES security enable or not
  [1] AES_NONCE_INIT — This bit enables the AES initialization with nonce
  [0] SET_IP_MODE — This bit enables the qspi interface pins into HiZ mode
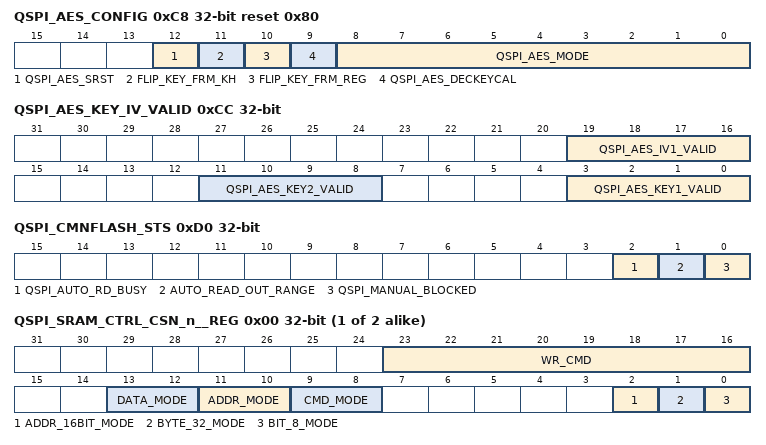
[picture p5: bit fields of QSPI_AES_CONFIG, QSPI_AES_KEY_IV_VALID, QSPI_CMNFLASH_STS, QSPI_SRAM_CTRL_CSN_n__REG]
0xC8 QSPI_AES_CONFIG reset 0x80 — QSPI AES CONFIG REG
  [12] QSPI_AES_SRST wo — Synchronous soft reset for AES Module. Write only bit. Reading this bit gives alway 0
  [11] FLIP_KEY_FRM_KH — writing 1 to this Flips the 32-bit endian key taken from kh
  [10] FLIP_KEY_FRM_REG — writing 1 to this Flips the 32-bit endian key taken from kh
  [9] QSPI_AES_DECKEYCAL — Enables pre-calculation of KEY before decryption operation
  [8:0] QSPI_AES_MODE — AES mode of decryption CTR/XTS
0xCC QSPI_AES_KEY_IV_VALID — QSPI AES KEYS and IVS VALID
  [19:16] QSPI_AES_IV1_VALID — Write enables for AES IV 1. Denotes which bytes of IV1 is valid
  [11:8] QSPI_AES_KEY2_VALID — Write enables for AES KEY 2. Denotes which bytes of key2 is valid
  [3:0] QSPI_AES_KEY1_VALID — Write enables for AES KEY 1. Denotes which bytes of key1 is valid
0xD0 QSPI_CMNFLASH_STS ro — QSPI Common Flash Status
  [2] QSPI_AUTO_RD_BUSY — 1 - Auto read transactions in progress.0 - No Auto read transactions
  [1] AUTO_READ_OUT_RANGE — 1- Auto read transaction is out of M4 Address range 0- Auto read transaction is in Address range
  [0] QSPI_MANUAL_BLOCKED — 1 - Manual read/write transaction initiated is blocked.0- No manual transactions
0xE4 QSPI_AES_SEC_SEG_LS_ADDR_1
  [31:0] QSPI_AES_SEC_SEG_LS_ADDR_1 — This register specifies the lower boundary address of 1st segment
0xE8 QSPI_AES_SEC_SEG_MS_ADDR_1
  [31:0] QSPI_AES_SEC_SEG_MS_ADDR_1 — This register specifies the upper boundary address of 1st segment
0xEC QSPI_AES_SEC_SEG_LS_ADDR_2
  [31:0] QSPI_AES_SEC_SEG_LS_ADDR_2 — This register specifies the lower boundary address of 2nd segment
0xF0 QSPI_AES_SEC_SEG_MS_ADDR_2
  [31:0] QSPI_AES_SEC_SEG_MS_ADDR_2 — This register specifies the upper boundary address of 2nd segment
0xF4 QSPI_AES_SEC_SEG_LS_ADDR_3
  [31:0] QSPI_AES_SEC_SEG_LS_ADDR_3 — This register specifies the lower boundary address of 3rd segment
0xF8 QSPI_AES_SEC_SEG_MS_ADDR_3
  [31:0] QSPI_AES_SEC_SEG_MS_ADDR_3 — This register specifies the upper boundary address of 3rd segment
0xFC QSPI_AES_SEC_SEG_LS_ADDR_4
  [31:0] QSPI_AES_SEC_SEG_LS_ADDR_4 — This register specifies the lower boundary address of 4th segment
0x100 QSPI_AES_SEC_SEG_MS_ADDR_4
  [31:0] QSPI_AES_SEC_SEG_MS_ADDR_4 — This register specifies the upper boundary address of 4th segment
{0x104+4i} QSPI_SRAM_CTRL_CSNn_REG[{i}] (i=0..1) group — QSPI SRAM CTRL CSN (0-1)
  0x00 QSPI_SRAM_CTRL_CSN_n__REG — QSPI SRAM CTRL CSN
    [23:16] WR_CMD — Command to be used for writing
    [13:12] DATA_MODE — writing address mode
      0=Single SPI; 1=Dual SPI; 2=Quad SPI; 3=OCTA SPI
    [11:10] ADDR_MODE — writing address mode
      0=Single SPI; 1=Dual SPI; 2=Quad SPI; 3=OCTA SPI
    [9:8] CMD_MODE — writing cmd mode
      0=Single SPI; 1=Dual SPI; 2=Quad SPI; 3=OCTA SPI
    [2] ADDR_16BIT_MODE — Send only lower 16bits of Address enable.
      0=24 address bit flash is connected; 1=16 address bit flash is connected
    [1] BYTE_32_MODE — Flash 32 byte boundary mode
      0=Flash is not with 32 byte boundary; 1=Flash is with 32 byte boundary
    [0] BIT_8_MODE — Flash 8bit (1 byte) boundary mode
      0=Flash is not with 8bit (1 byte) boundary; 1=Flash is with 8bit (1 byte) boundary
0x11C SEMI_AUTO_MODE_ADDR_REG — Byte address to read the data from flash in semi auto mode. It is valid only semi auto mode enable bit is asserted
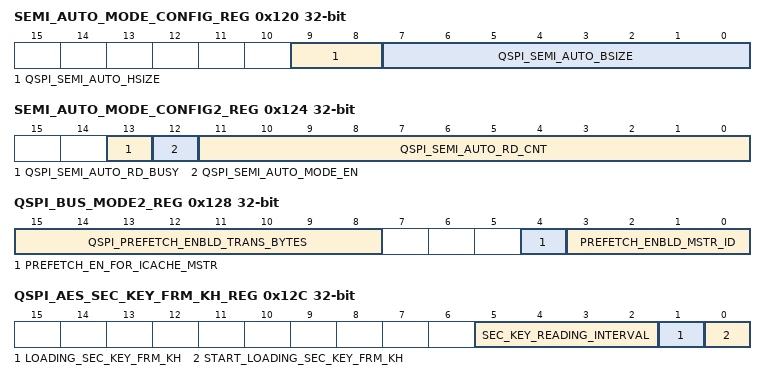
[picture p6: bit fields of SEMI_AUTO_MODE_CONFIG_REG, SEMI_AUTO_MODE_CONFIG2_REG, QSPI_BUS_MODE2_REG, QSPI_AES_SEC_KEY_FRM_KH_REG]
0x120 SEMI_AUTO_MODE_CONFIG_REG
  [9:8] QSPI_SEMI_AUTO_HSIZE — Indicates number of bytes valid in each transaction
    0=1 byte valid; 1=2 bytes valid; 2=4 bytes valid; 3=none
  [7:0] QSPI_SEMI_AUTO_BSIZE — This is burst size to read data from flash in semi auto mode
0x124 SEMI_AUTO_MODE_CONFIG2_REG
  [13] QSPI_SEMI_AUTO_RD_BUSY — Indicates status of semi auto mode read status. If it is high, semi auto mode read operation is progressing
  [12] QSPI_SEMI_AUTO_MODE_EN — Enable for semi auto mode read operation. Make sure manual mode read/write operation is completed before asserting this bit
  [11:0] QSPI_SEMI_AUTO_RD_CNT — Total number of bytes to be read flash continuously from the address given by SEMI_AUTO_MODE_ADDR_REG
0x128 QSPI_BUS_MODE2_REG
  [15:8] QSPI_PREFETCH_ENBLD_TRANS_BYTES — Programmable prefetch enabled AHB master transfer bytes. Assume this is used for icache and dma ahb master access in auto mode.
  [4] PREFETCH_EN_FOR_ICACHE_MSTR — Prefetch enable for icache AHB master.
  [3:0] PREFETCH_ENBLD_MSTR_ID — Holds the programmable prefetch enabled AHB master ID. This is commonly used for enabling prefetch for icache master.
0x12C QSPI_AES_SEC_KEY_FRM_KH_REG
  [5:2] SEC_KEY_READING_INTERVAL — Security key reading interval
  [1] LOADING_SEC_KEY_FRM_KH ro — Indicates security key loading status from KH.
  [0] START_LOADING_SEC_KEY_FRM_KH wo — Start Security key loading from KH.
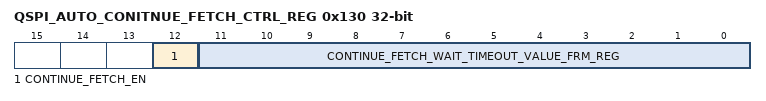
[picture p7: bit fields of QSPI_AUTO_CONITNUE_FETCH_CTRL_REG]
0x130 QSPI_AUTO_CONITNUE_FETCH_CTRL_REG
  [12] CONTINUE_FETCH_EN — Continue fetch feature enable.
  [11:0] CONTINUE_FETCH_WAIT_TIMEOUT_VALUE_FRM_REG — Maximum Continue fetch wait time between two qspi auto reads.
0x134 QSPI_AES_KEY1_0_3
  [31:0] QSPI_AES_KEY1_0_3 — To hold first 3-0 bytes of aes key1 as 0 referred as lsb in the key
0x138 QSPI_AES_KEY1_4_7
  [31:0] QSPI_AES_KEY1_4_7 — To hold first 7-4 bytes of aes key1 as 0 referred as lsb
0x13C QSPI_AES_KEY1_8_B
  [31:0] QSPI_AES_KEY1_8_B — To hold first 11-8 bytes of aes key1 as 0 referred as lsb
0x140 QSPI_AES_KEY1_C_F
  [31:0] QSPI_AES_KEY1_C_F — To hold first 11-8 bytes of aes key1 as 0 referred as lsb
0x154 QSPI_AES_KEY2_0_3
  [31:0] QSPI_AES_KEY2_0_3 — To hold first 3-0 bytes of aes key2 as 0 referred as lsb in the key
0x158 QSPI_AES_KEY2_4_7
  [31:0] QSPI_AES_KEY2_4_7 — To hold first 7-4 bytes of aes key2 as 0 referred as lsb
0x15C QSPI_AES_KEY2_8_B
  [31:0] QSPI_AES_KEY2_8_B — To hold first 11-8 bytes of aes key2 as 0 referred as lsb
0x160 QSPI_AES_KEY2_C_F
  [31:0] QSPI_AES_KEY2_C_F — To hold first 15-12 bytes of aes key2 as 0 referred as lsb
